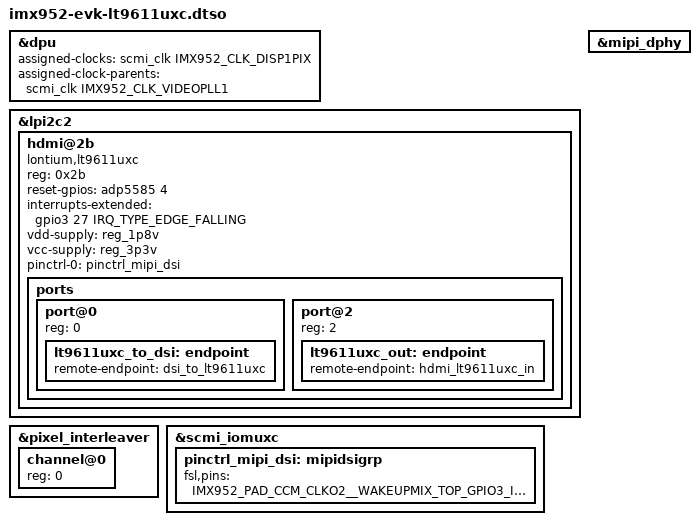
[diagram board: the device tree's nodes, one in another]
// SPDX-License-Identifier: (GPL-2.0+ OR MIT)
/*
 * Copyright 2026 NXP
 */

/dts-v1/;
/plugin/;

#include "imx952-clock.h"
#include "imx952-pinfunc.h"
#include "imx95-lt9611uxc-common.dtsi"

&dpu {
	assigned-clocks = <&scmi_clk IMX952_CLK_DISP1PIX>;
	assigned-clock-parents = <&scmi_clk IMX952_CLK_VIDEOPLL1>;
};

&lpi2c2 {
	#address-cells = <1>;
	#size-cells = <0>;

	hdmi@2b {
		compatible = "lontium,lt9611uxc";
		reg = <0x2b>;
		reset-gpios = <&adp5585 4 GPIO_ACTIVE_HIGH>;
		interrupts-extended = <&gpio3 27 IRQ_TYPE_EDGE_FALLING>;

		vdd-supply = <&reg_1p8v>;
		vcc-supply = <&reg_3p3v>;

		pinctrl-names = "default";
		pinctrl-0 = <&pinctrl_mipi_dsi>;

		ports {
			#address-cells = <1>;
			#size-cells = <0>;

			port@0 {
				reg = <0>;

				lt9611uxc_to_dsi: endpoint {
					remote-endpoint = <&dsi_to_lt9611uxc>;
				};
			};

			port@2 {
				reg = <2>;

				lt9611uxc_out: endpoint {
					remote-endpoint = <&hdmi_lt9611uxc_in>;
				};
			};
		};
	};
};

&mipi_dphy {
	status = "okay";
};

&pixel_interleaver {
	#address-cells = <1>;
	#size-cells = <0>;
	status = "okay";

	channel@0 {
		reg = <0>;
		status = "okay";
	};
};

&scmi_iomuxc {
	pinctrl_mipi_dsi: mipidsigrp {
		fsl,pins = <
			IMX952_PAD_CCM_CLKO2__WAKEUPMIX_TOP_GPIO3_IO_27	0x31e
		>;
	};
};
